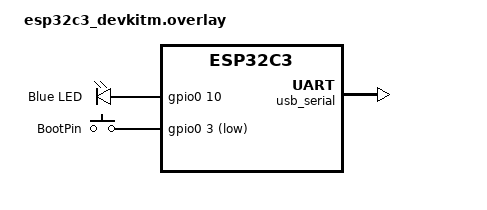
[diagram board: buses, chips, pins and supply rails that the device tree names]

/ {
    aliases {
        mcuboot-led0 = &blue_led;
        mcuboot-button0 = &boot_pin;
    };

    chosen {
        zephyr,code-partition = &boot_partition;
        zephyr,boot-serial-uart = &usb_serial;
    };


	leds {
		compatible = "gpio-leds";

		blue_led: led_0 {
			gpios = <&gpio0 10 GPIO_ACTIVE_HIGH>;
			label = "Blue LED";
		};
	};

	keys {
		compatible = "gpio-keys";

		boot_pin: boot_pin_3  {
			label = "BootPin";
			gpios = <&gpio0 3 (GPIO_PULL_UP | GPIO_ACTIVE_LOW)>;
		};
	};
};

&usb_serial {
	status = "okay";
};
